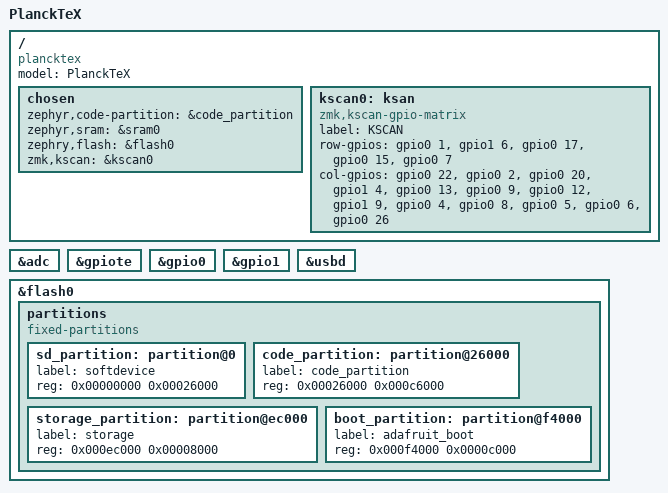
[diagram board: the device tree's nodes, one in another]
#include <nordic/nrf52840_qiaa.dtsi>
/{
	model = "PlanckTeX";
	compatible = "plancktex";

	chosen{
		zephyr,code-partition = &code_partition;
		zephyr,sram = &sram0;
		zephry,flash = &flash0;
		zmk,kscan = &kscan0;
	};

	kscan0: ksan{
		compatible = "zmk,kscan-gpio-matrix";
		label = "KSCAN";
		row-gpios
			= <&gpio0 1  (GPIO_ACTIVE_HIGH | GPIO_PULL_DOWN)>
			, <&gpio1 6  (GPIO_ACTIVE_HIGH | GPIO_PULL_DOWN)>
			, <&gpio0 17 (GPIO_ACTIVE_HIGH | GPIO_PULL_DOWN)>
			, <&gpio0 15 (GPIO_ACTIVE_HIGH | GPIO_PULL_DOWN)>
			, <&gpio0 7  (GPIO_ACTIVE_HIGH | GPIO_PULL_DOWN)>
			;
		col-gpios
			= <&gpio0 22 GPIO_ACTIVE_HIGH>
			, <&gpio0 2  GPIO_ACTIVE_HIGH>
			, <&gpio0 20 GPIO_ACTIVE_HIGH>
			, <&gpio1 4  GPIO_ACTIVE_HIGH>
			, <&gpio0 13 GPIO_ACTIVE_HIGH>
			, <&gpio0 9  GPIO_ACTIVE_HIGH>
			, <&gpio0 12 GPIO_ACTIVE_HIGH>
			, <&gpio1 9  GPIO_ACTIVE_HIGH>
			, <&gpio0 4  GPIO_ACTIVE_HIGH>
			, <&gpio0 8  GPIO_ACTIVE_HIGH>
			, <&gpio0 5  GPIO_ACTIVE_HIGH>
			, <&gpio0 6  GPIO_ACTIVE_HIGH>
			, <&gpio0 26 GPIO_ACTIVE_HIGH>
			;

	};


};

&adc {
	status = "okay";
};

&gpiote {
	status = "okay";
};

&gpio0 {
       status = "okay";
};

&gpio1 {
       status = "okay";
}

&usbd {
      status = "okay";
}

&flash0 {
	/*
	 * For more information, see:
	 * http://docs.zephyrproject.org/latest/devices/dts/flash_partitions.html
	 */
	partitions {
		compatible = "fixed-partitions";
		#address-cells = <1>;
		#size-cells = <1>;

		sd_partition: partition@0 {
			label = "softdevice";
			reg = <0x00000000 0x00026000>;
		};
		code_partition: partition@26000 {
			label = "code_partition";
			reg = <0x00026000 0x000c6000>;
		};

		/*
		 * The flash starting at 0x000ec000 and ending at
		 * 0x000f3fff is reserved for use by the application.
		 */

		/*
		 * Storage partition will be used by FCB/LittleFS/NVS
		 * if enabled.
		 */
		storage_partition: partition@ec000 {
			label = "storage";
			reg = <0x000ec000 0x00008000>;
		};

		boot_partition: partition@f4000 {
			label = "adafruit_boot";
			reg = <0x000f4000 0x0000c000>;
		};
	};
};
